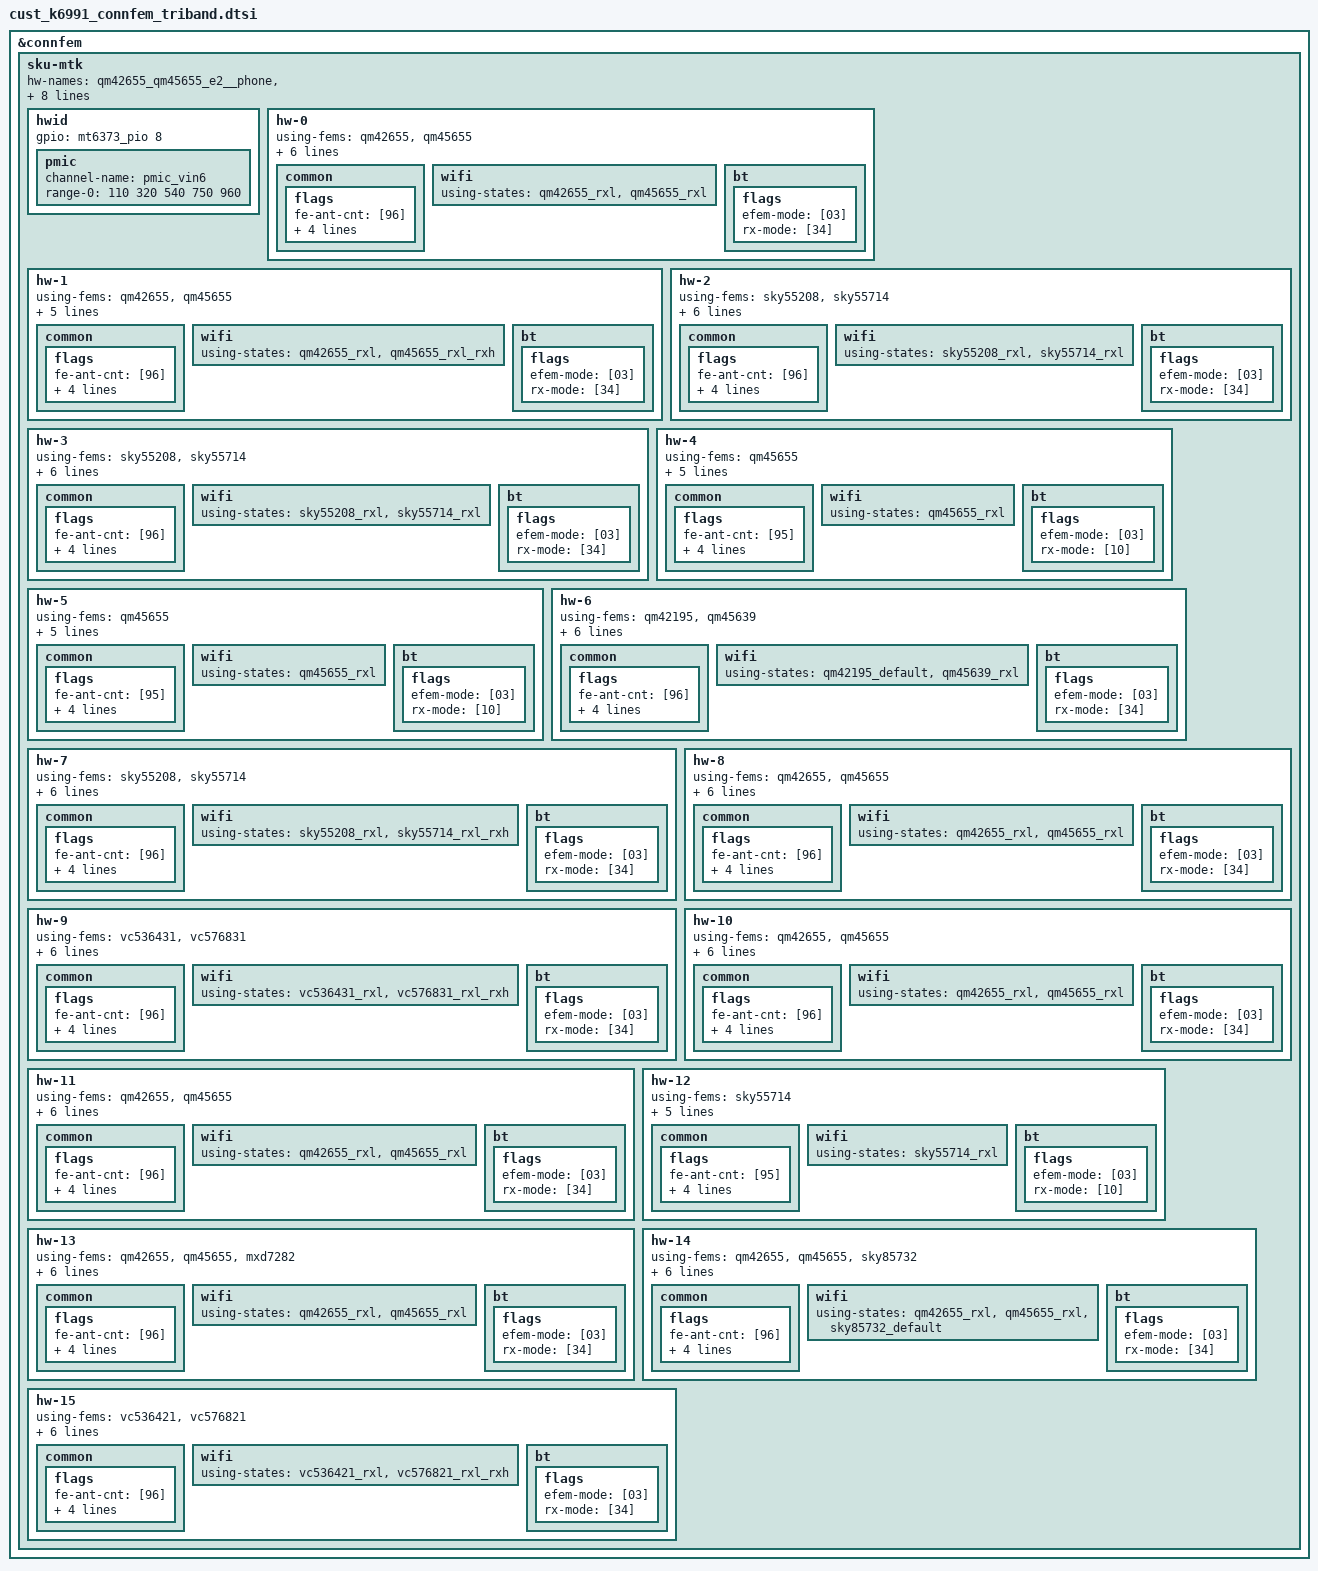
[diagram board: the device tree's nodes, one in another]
// SPDX-License-Identifier: (GPL-2.0 OR MIT)
/*
 * Copyright (c) 2020 MediaTek Inc.
 */
/* Connsys FEM Start */
&connfem {
	sku-mtk {
		hw-names =
			"qm42655_qm45655_e2__phone",	/* [0] SKU1-1 Phone Qorvo E2 */
			"qm42655_qm45655_was",		/* [1] SKU5-1 EVB Qorvo E3 */
			"sky55208_sky55714",		/* [2] SKU1-2 Phone (N/A) */
			"sky55208_sky55714",		/* [3] SKU1-2 EVB */
			"ipa_qm45655__phone",		/* [4] SKU2 Phone */
			"ipa_qm45655",			/* [5] SKU2 EVB */
			"sku1_backup",			/* [6] SKU1 Backup Phone (N/A) */
			"sky55208_sky55714_was",	/* [7] SKU5-2 EVB */
			"sku3__phone",			/* [8] SKU3 Phone */
			"vc536431_vc576831_was",	/* [9] SKU5-3 EVB */
			"qm42655_qm45655__phone",	/* [10] SKU1-3 Qorvo E3 Phone */
			"qm42655_qm45655",		/* [11] SKU1-1 Qorvo E3 EVB */
			"ipa_sky55714",			/* [12] SKU2 SKY55714 */
			"qm42655_qm45655_e2",		/* [13] SKU1 Qorvo E2 MXD7282 BT eFEM */
			"qm42655_qm45655_sky85732",	/* [14] SKU1 Qorvo E3 BN2 SKY85732 2A+1A */
			"vc536421_vc576821";		/* [15] SKU1 VC536421/576821 */

		hwid {
			/* HWID bit[0]
			 *	0: Phone
			 *	1: EVB
			 */
			gpio = <&mt6373_pio 8 0x0>;

			/* HWID bit[3:1]
			 *	3'b000: SKU1-1
			 *	3'b001: SKU1-2
			 *	3'b010: SKU2
			 *	3'b011: SKU1 Backup
			 *	3'b100: SKU3
			 *	3'b101: SKU1-1 (E3)
			 */
			pmic {
				channel-name = "pmic_vin6";
				range-0 = <110 320 540 750 960>;
			};
		};

		/***************************************************************
		 * [HW][0] SKU1-1 Phone
		 **************************************************************/
		hw-0 {
			using-fems =
				<&qm42655>,
				<&qm45655>;

			layout-flag = <0x00000000>;
			layout =
				<&g_wf0_bt0_qm42655>,
				<&g_wf1_bt1_qm42655>,
				<&a_wf0_qm45655>,
				<&a_wf1_qm45655>,
				<&a_wf2_bt0_qm45655>;

			layout-spdt =
				<&spdt_a2_filter>,
				<&spdt_g_bt1_antswap>;

			common {
				flags {
					fe-ant-cnt = [96];
					fe-conn-dpdt-sp3t = [80];
					fe-conn-spdt = [98];
					fe-bt-wf-usage = [98];
					fe-conn-spdt-2 = [80];
				};
			};

			wifi {
				using-states =
					<&qm42655_rxl>,
					<&qm45655_rxl>;
			};

			bt {
				flags {
					efem-mode = [03]; /* 3:epa_elna, 2:epa, 1:elna, 0:bypass */
					rx-mode = [34]; /* 0x34: G-band RxL, HBBT RxH */
				};
			};
		};

		/***************************************************************
		 * [HW][1] SKU5-1 EVB
		 **************************************************************/
		hw-1 {
			using-fems =
				<&qm42655>,
				<&qm45655>;

			layout-flag = <0x00000000>;
			layout =
				<&g_wf0_bt0_qm42655>,
				<&g_wf1_bt1_qm42655>,
				<&a_wf0_qm45655>,
				<&a_wf12_emlsr_bt0_qm45655>;

			layout-spdt =
				<&spdt_a1_a2_tx>,
				<&spdt_a1_a2_rx>,
				<&spdt_a_wf0_antswap>,
				<&spdt_g_bt1_antswap>;

			common {
				flags {
					fe-ant-cnt = [96];
					fe-conn-dpdt-sp3t = [80];
					fe-conn-spdt = [93];
					fe-bt-wf-usage = [88];
					fe-conn-spdt-2 = [90];
				};
			};

			wifi {
				using-states =
					<&qm42655_rxl>,
					<&qm45655_rxl_rxh>;
			};

			bt {
				flags {
					efem-mode = [03]; /* 3:epa_elna, 2:epa, 1:elna, 0:bypass */
					rx-mode = [34]; /* 0x34: G-band RxL, HBBT RxH */
				};
			};
		};

		/***************************************************************
		 * [HW][2] SKU1-2 Phone (N/A)
		 **************************************************************/
		hw-2 {
			using-fems =
				<&sky55208>,
				<&sky55714>;

			layout-flag = <0x00000000>;
			layout =
				<&g_wf0_bt0_sky55208>,
				<&g_wf1_bt1_sky55208>,
				<&a_wf0_sky55714>,
				<&a_wf1_sky55714>,
				<&a_wf2_bt0_sky55714>;

			layout-spdt =
				<&spdt_a2_filter>,
				<&spdt_g_bt1_antswap>;

			common {
				flags {
					fe-ant-cnt = [96];
					fe-conn-dpdt-sp3t = [80];
					fe-conn-spdt = [98];
					fe-bt-wf-usage = [98];
					fe-conn-spdt-2 = [80];
				};
			};

			wifi {
				using-states =
					<&sky55208_rxl>,
					<&sky55714_rxl>;
			};

			bt {
				flags {
					efem-mode = [03]; /* 3:epa_elna, 2:epa, 1:elna, 0:bypass */
					rx-mode = [34]; /* 0x34: G-band RxL, HBBT RxH */
				};
			};
		};

		/***************************************************************
		 * [HW][3] SKU1-2 EVB
		 **************************************************************/
		hw-3 {
			using-fems =
				<&sky55208>,
				<&sky55714>;

			layout-flag = <0x00000000>;
			layout =
				<&g_wf0_bt0_sky55208>,
				<&g_wf1_bt1_sky55208>,
				<&a_wf0_sky55714>,
				<&a_wf1_sky55714>,
				<&a_wf2_bt0_sky55714>;

			layout-spdt =
				<&spdt_a2_filter>,
				<&spdt_g_bt1_antswap>;

			common {
				flags {
					fe-ant-cnt = [96];
					fe-conn-dpdt-sp3t = [80];
					fe-conn-spdt = [98];
					fe-bt-wf-usage = [98];
					fe-conn-spdt-2 = [80];
				};
			};

			wifi {
				using-states =
					<&sky55208_rxl>,
					<&sky55714_rxl>;
			};

			bt {
				flags {
					efem-mode = [03]; /* 3:epa_elna, 2:epa, 1:elna, 0:bypass */
					rx-mode = [34]; /* 0x34: G-band RxL, HBBT RxH */
				};
			};
		};

		/***************************************************************
		 * [HW][4] SKU2 Phone
		 **************************************************************/
		hw-4 {
			using-fems = <&qm45655>;

			layout-flag = <0x00000000>;
			layout =
				<&a_wf0_qm45655>,
				<&a_wf12_emlsr_bt0_qm45655>;

			layout-spdt =
				<&spdt_a1_a2_tx>,
				<&spdt_a1_a2_rx>,
				<&sp3t_g0_ipa>,
				<&sp3t_g1_ipa>,
				<&spdt_laa_ctrl>;

			common {
				flags {
					fe-ant-cnt = [95];
					fe-conn-dpdt-sp3t = [e0];
					fe-conn-spdt = [83];
					fe-bt-wf-usage = [88];
					fe-conn-spdt-2 = [86];
				};
			};

			wifi {
				using-states = <&qm45655_rxl>;
			};

			bt {
				flags {
					efem-mode = [03]; /* 3:epa_elna, 2:epa, 1:elna, 0:bypass */
					rx-mode = [10]; /* 0x10: HBBT RxH */
				};
			};
		};

		/***************************************************************
		 * [HW][5] SKU2 EVB
		 **************************************************************/
		hw-5 {
			using-fems = <&qm45655>;

			layout-flag = <0x00000000>;
			layout =
				<&a_wf0_qm45655>,
				<&a_wf12_emlsr_bt0_qm45655>;

			layout-spdt =
				<&spdt_a1_a2_tx>,
				<&spdt_a1_a2_rx>,
				<&sp3t_g0_ipa>,
				<&sp3t_g1_ipa>,
				<&spdt_laa_ctrl>;

			common {
				flags {
					fe-ant-cnt = [95];
					fe-conn-dpdt-sp3t = [e0];
					fe-conn-spdt = [83];
					fe-bt-wf-usage = [88];
					fe-conn-spdt-2 = [86];
				};
			};

			wifi {
				using-states = <&qm45655_rxl>;
			};

			bt {
				flags {
					efem-mode = [03]; /* 3:epa_elna, 2:epa, 1:elna, 0:bypass */
					rx-mode = [10]; /* 0x10: HBBT RxH */
				};
			};
		};

		/***************************************************************
		 * [HW][6] SKU1 Backup Phone (N/A)
		 **************************************************************/
		hw-6 {
			using-fems =
				<&qm42195>,
				<&qm45639>;

			layout-flag = <0x00000000>;
			layout =
				<&g_wf0_bt0_qm42195>,
				<&g_wf1_bt1_qm42195>,
				<&a_wf0_qm45639>,
				<&a_wf1_qm45639>,
				<&a_wf2_bt0_qm45639>;

			layout-spdt =
				<&spdt_a2_filter>,
				<&spdt_g_bt1_antswap>;

			common {
				flags {
					fe-ant-cnt = [96];
					fe-conn-dpdt-sp3t = [80];
					fe-conn-spdt = [98];
					fe-bt-wf-usage = [98];
					fe-conn-spdt-2 = [80];
				};
			};

			wifi {
				using-states =
					<&qm42195_default>,
					<&qm45639_rxl>;
			};

			bt {
				flags {
					efem-mode = [03]; /* 3:epa_elna, 2:epa, 1:elna, 0:bypass */
					rx-mode = [34]; /* 0x34: G-band RxL, HBBT RxH */
				};
			};
		};

		/***************************************************************
		 * [HW][7] SKU5-2 EVB
		 **************************************************************/
		hw-7 {
			using-fems =
				<&sky55208>,
				<&sky55714>;

			layout-flag = <0x00000000>;
			layout =
				<&g_wf0_bt0_sky55208>,
				<&g_wf1_bt1_sky55208>,
				<&a_wf0_sky55714>,
				<&a_wf12_emlsr_bt0_sky55714>;

			layout-spdt =
				<&spdt_a1_a2_tx>,
				<&spdt_a1_a2_rx>,
				<&spdt_a_wf0_antswap>,
				<&spdt_g_bt1_antswap>;

			common {
				flags {
					fe-ant-cnt = [96];
					fe-conn-dpdt-sp3t = [80];
					fe-conn-spdt = [93];
					fe-bt-wf-usage = [88];
					fe-conn-spdt-2 = [90];
				};
			};

			wifi {
				using-states =
					<&sky55208_rxl>,
					<&sky55714_rxl_rxh>;
			};

			bt {
				flags {
					efem-mode = [03]; /* 3:epa_elna, 2:epa, 1:elna, 0:bypass */
					rx-mode = [34]; /* 0x34: G-band RxL, HBBT RxH */
				};
			};
		};

		/***************************************************************
		 * [HW][8] SKU3 Phone
		 **************************************************************/
		hw-8 {
			using-fems =
				<&qm42655>,
				<&qm45655>;

			layout-flag = <0x00000000>;
			layout =
				<&g_wf0_bt0_qm42655>,
				<&g_wf1_bt1_qm42655>,
				<&a_wf0_qm45655>,
				<&a_wf1_qm45655>,
				<&a_wf2_bt0_qm45655>;

			layout-spdt =
				<&spdt_a2_filter>,
				<&spdt_g_bt1_antswap>,
				<&spdt_laa_ctrl>;

			common {
				flags {
					fe-ant-cnt = [96];
					fe-conn-dpdt-sp3t = [80];
					fe-conn-spdt = [98];
					fe-bt-wf-usage = [98];
					fe-conn-spdt-2 = [86];
				};
			};

			wifi {
				using-states =
					<&qm42655_rxl>,
					<&qm45655_rxl>;
			};

			bt {
				flags {
					efem-mode = [03]; /* 3:epa_elna, 2:epa, 1:elna, 0:bypass */
					rx-mode = [34]; /* 0x34: G-band RxL, HBBT RxH */
				};
			};
		};

		/***************************************************************
		 * [HW][9] SKU5-3 EVB
		 **************************************************************/
		hw-9 {
			using-fems =
				<&vc536431>,
				<&vc576831>;

			layout-flag = <0x00000000>;
			layout =
				<&g_wf0_bt0_vc536431>,
				<&g_wf1_bt1_vc536431>,
				<&a_wf0_vc576831>,
				<&a_wf12_emlsr_bt0_vc576831>;

			layout-spdt =
				<&spdt_a1_a2_tx>,
				<&spdt_a1_a2_rx>,
				<&spdt_a_wf0_antswap>,
				<&spdt_g_bt1_antswap>;

			common {
				flags {
					fe-ant-cnt = [96];
					fe-conn-dpdt-sp3t = [80];
					fe-conn-spdt = [93];
					fe-bt-wf-usage = [88];
					fe-conn-spdt-2 = [90];
				};
			};

			wifi {
				using-states =
					<&vc536431_rxl>,
					<&vc576831_rxl_rxh>;
			};

			bt {
				flags {
					efem-mode = [03]; /* 3:epa_elna, 2:epa, 1:elna, 0:bypass */
					rx-mode = [34]; /* 0x34: G-band RxL, HBBT RxH */
				};
			};
		};

		/***************************************************************
		 * [HW][10] SKU1-1 E3 Phone
		 **************************************************************/
		hw-10 {
			using-fems =
				<&qm42655>,
				<&qm45655>;

			layout-flag = <0x00000000>;
			layout =
				<&g_wf0_bt0_qm42655>,
				<&g_wf1_bt1_qm42655>,
				<&a_wf0_qm45655>,
				<&a_wf1_qm45655>,
				<&a_wf2_bt0_qm45655>;

			layout-spdt =
				<&spdt_a2_filter>,
				<&spdt_g_bt1_antswap>;

			common {
				flags {
					fe-ant-cnt = [96];
					fe-conn-dpdt-sp3t = [80];
					fe-conn-spdt = [98];
					fe-bt-wf-usage = [98];
					fe-conn-spdt-2 = [80];
				};
			};

			wifi {
				using-states =
					<&qm42655_rxl>,
					<&qm45655_rxl>;
			};

			bt {
				flags {
					efem-mode = [03]; /* 3:epa_elna, 2:epa, 1:elna, 0:bypass */
					rx-mode = [34]; /* 0x34: G-band RxL, HBBT RxH */
				};
			};
		};

		/***************************************************************
		 * [HW][11] SKU1-1 E3 EVB
		 **************************************************************/
		hw-11 {
			using-fems =
				<&qm42655>,
				<&qm45655>;

			layout-flag = <0x00000000>;
			layout =
				<&g_wf0_bt0_qm42655>,
				<&g_wf1_bt1_qm42655>,
				<&a_wf0_qm45655>,
				<&a_wf1_qm45655>,
				<&a_wf2_bt0_qm45655>;

			layout-spdt =
				<&spdt_a2_filter>,
				<&spdt_g_bt1_antswap>;

			common {
				flags {
					fe-ant-cnt = [96];
					fe-conn-dpdt-sp3t = [80];
					fe-conn-spdt = [98];
					fe-bt-wf-usage = [98];
					fe-conn-spdt-2 = [80];
				};
			};

			wifi {
				using-states =
					<&qm42655_rxl>,
					<&qm45655_rxl>;
			};

			bt {
				flags {
					efem-mode = [03]; /* 3:epa_elna, 2:epa, 1:elna, 0:bypass */
					rx-mode = [34]; /* 0x34: G-band RxL, HBBT RxH */
				};
			};
		};

		/***************************************************************
		 * [HW][12] SKU2 with SKY55714
		 **************************************************************/
		hw-12 {
			using-fems = <&sky55714>;

			layout-flag = <0x00000000>;
			layout =
				<&a_wf0_sky55714>,
				<&a_wf12_emlsr_bt0_sky55714>;

			layout-spdt =
				<&spdt_a1_a2_tx>,
				<&spdt_a1_a2_rx>,
				<&sp3t_g0_ipa>,
				<&sp3t_g1_ipa>,
				<&spdt_laa_ctrl>;

			common {
				flags {
					fe-ant-cnt = [95];
					fe-conn-dpdt-sp3t = [e0];
					fe-conn-spdt = [83];
					fe-bt-wf-usage = [88];
					fe-conn-spdt-2 = [86];
				};
			};

			wifi {
				using-states = <&sky55714_rxl>;
			};

			bt {
				flags {
					efem-mode = [03]; /* 3:epa_elna, 2:epa, 1:elna, 0:bypass */
					rx-mode = [10]; /* 0x10: HBBT RxH */
				};
			};
		};

		/***************************************************************
		 * [HW][13] SKU1-1 with MXD7282 BT eFEM
		 **************************************************************/
		hw-13 {
			using-fems =
				<&qm42655>,
				<&qm45655>,
				<&mxd7282>;

			layout-flag = <0x00000000>;
			layout =
				<&g_wf0_bt0_qm42655>,
				<&g_wf1_bt1_qm42655>,
				<&a_wf0_qm45655>,
				<&a_wf1_qm45655>,
				<&a_wf2_bt0_qm45655>,
				<&g_bt1_mxd7282>;

			layout-spdt =
				<&spdt_a2_filter>,
				<&spdt_g_bt1_antswap>;

			common {
				flags {
					fe-ant-cnt = [96];
					fe-conn-dpdt-sp3t = [80];
					fe-conn-spdt = [98];
					fe-bt-wf-usage = [98];
					fe-conn-spdt-2 = [80];
				};
			};

			wifi {
				using-states =
					<&qm42655_rxl>,
					<&qm45655_rxl>;
			};

			bt {
				flags {
					efem-mode = [03]; /* 3:epa_elna, 2:epa, 1:elna, 0:bypass */
					rx-mode = [34]; /* 0x34: G-band RxL, HBBT RxH */
				};
			};
		};

		/***************************************************************
		 * [HW][14] sku1-1 BN2 SKY85732 2G+2A+1A
		 **************************************************************/
		hw-14 {
			using-fems =
				<&qm42655>,
				<&qm45655>,
				<&sky85732>;

			layout-flag = <0x00000000>;
			layout =
				<&g_wf0_bt0_qm42655>,
				<&g_wf1_bt1_qm42655>,
				<&a_wf0_qm45655>,
				<&a_wf1_qm45655>,
				<&a_wf2_bt0_sky85732>;

			layout-spdt =
				<&spdt_a2_filter>,
				<&spdt_g_bt1_antswap>;

			common {
				flags {
					fe-ant-cnt = [96];
					fe-conn-dpdt-sp3t = [80];
					fe-conn-spdt = [98];
					fe-bt-wf-usage = [98];
					fe-conn-spdt-2 = [80];
				};
			};

			wifi {
				using-states =
					<&qm42655_rxl>,
					<&qm45655_rxl>,
					<&sky85732_default>;
			};

			bt {
				flags {
					efem-mode = [03]; /* 3:epa_elna, 2:epa, 1:elna, 0:bypass */
					rx-mode = [34]; /* 0x34: G-band RxL, HBBT RxH */
				};
			};
		};

		/***************************************************************
		 * [HW][15] SKU1 Vanchip-21 DTB
		 **************************************************************/
		hw-15 {
			using-fems =
				<&vc536421>,
				<&vc576821>;

			layout-flag = <0x00000000>;
			layout =
				<&g_wf0_bt0_vc536421>,
				<&g_wf1_bt1_vc536421>,
				<&a_wf0_vc576821>,
				<&a_wf1_vc576821>,
				<&a_wf2_bt0_vc576821>;

			layout-spdt =
				<&spdt_a2_filter>,
				<&spdt_g_bt1_antswap>;

			common {
				flags {
					fe-ant-cnt = [96];
					fe-conn-dpdt-sp3t = [80];
					fe-conn-spdt = [98];
					fe-bt-wf-usage = [98];
					fe-conn-spdt-2 = [80];
				};
			};

			wifi {
				using-states =
					<&vc536421_rxl>,
					<&vc576821_rxl_rxh>;
			};

			bt {
				flags {
					efem-mode = [03]; /* 3:epa_elna, 2:epa, 1:elna, 0:bypass */
					rx-mode = [34]; /* 0x34: G-band RxL, HBBT RxH */
				};
			};
		};
	};
};
/* Connsys FEM End */
